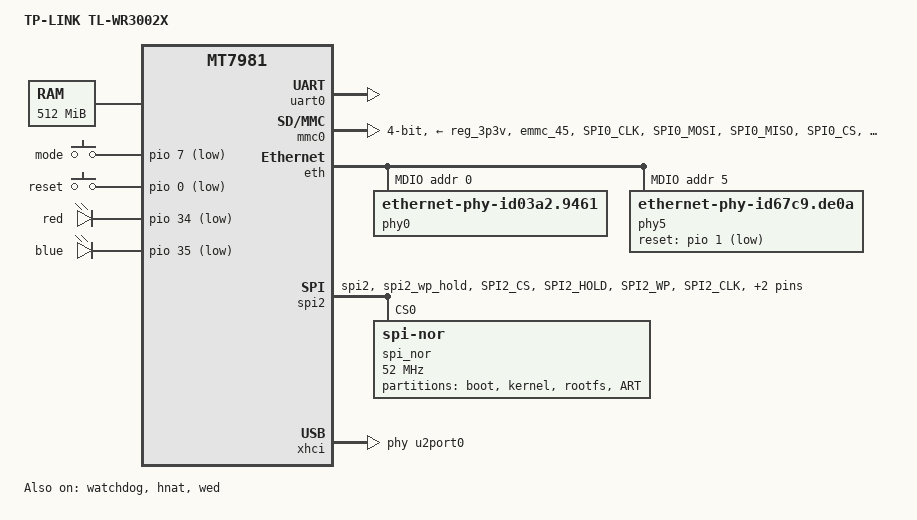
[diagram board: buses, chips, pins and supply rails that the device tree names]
/dts-v1/;
#include "mt7981.dtsi"
/ {
	model = "TP-LINK TL-WR3002X";
	compatible = "tplink,tl-wr3002x-v1", "mediatek,mt7981";
	chosen {
		bootargs = "console=ttyS0,115200n1 loglevel=8  \
				earlycon=uart8250,mmio32,0x11002000";
	};

	memory {
		// fpga ddr2: 512MB
		reg = <0 0x40000000 0 0x20000000>;
	};

	gpio-keys {
		compatible = "gpio-keys";
		mode {
			label = "mode";
			linux,code = <BTN_2>;
			gpios = <&pio 7 GPIO_ACTIVE_LOW>;
		};
	};
	gpio-keys-polled {
		compatible = "gpio-keys-polled";
		poll-interval = <100>;

		reset {
			label = "reset";
			linux,code = <KEY_RESTART>;
			gpios = <&pio 0 GPIO_ACTIVE_LOW>;
			linux,input-type = <1>;
		};
	};
	leds {
		compatible = "gpio-leds";	

		red {
			gpios = <&pio 34 GPIO_ACTIVE_LOW>;
			default-state = "off";
		};
		blue {
			gpios = <&pio 35 GPIO_ACTIVE_LOW>;
			linux,default-trigger = "timer";
		};
	};
};

&uart0 {
	status = "okay";
};

&watchdog {
	status = "okay";
};

&mmc0 {
         pinctrl-names = "default", "state_uhs";
         pinctrl-0 = <&mmc0_pins_default>;
         pinctrl-1 = <&mmc0_pins_uhs>;
         bus-width = <4>;
         max-frequency = <50000000>;
         cap-sd-highspeed;
         cd-gpios = <&pio 5 GPIO_ACTIVE_LOW>;
         wp-gpios = <&pio 8 GPIO_ACTIVE_LOW>;
         vmmc-supply = <&reg_3p3v>;
         vqmmc-supply = <&reg_3p3v>;
         status = "okay";
};

&eth {
        status = "okay";

        gmac0: mac@0 {
                compatible = "mediatek,eth-mac";
                reg = <0>;
                phy-mode = "2500base-x";
                nick-index = <0>;

                fixed-link {
                        speed = <2500>;
                        full-duplex;
                        pause;
                        link-gpio = <&pio 13 0>;
                        phy-handle = <&phy5>;
                        label = "eth0";
                };
        };

        gmac1: mac@1 {
                compatible = "mediatek,eth-mac";
                reg = <1>;
                phy-mode = "gmii";
                phy-handle = <&phy0>;
                nick-index = <1>;
        };

        mdio: mdio-bus {
                #address-cells = <1>;
                #size-cells = <0>;

                phy0: ethernet-phy@0 {
                    compatible = "ethernet-phy-id03a2.9461";
                    reg = <0>;
                    phy-mode = "gmii";
                    nvmem-cells = <&phy_calibration>;
                    nvmem-cell-names = "phy-cal-data";
                };

                phy5: phy@5 {
                        compatible = "ethernet-phy-id67c9.de0a";
                        reg = <5>;
                        reset-gpios = <&pio 1 1>;
                        reset-assert-us = <600>;
                        reset-deassert-us = <20000>;
                        phy-mode = "2500base-x";
                        partner_gmac = <0>;
                };
        };
};

&hnat {
	mtketh-wan = "eth0";
	mtketh-lan = "eth1";
	mtketh-ppd = "eth1";
	mtketh-gmac-mode = <2>;
	mtketh-max-gmac = <2>;
	status = "okay";
};

&spi1 {
	pinctrl-names = "default";
	pinctrl-0 = <&spic_pins>;
	status = "disabled";
};

&spi2 {
	pinctrl-names = "default";
	pinctrl-0 = <&spi2_flash_pins>;
	status = "okay";
	spi_nor@0 {
		#address-cells = <1>;
		#size-cells = <1>;
		compatible = "jedec,spi-nor";
		spi-cal-enable;
		spi-cal-mode = "read-data";
		spi-cal-datalen = <7>;
		spi-cal-data = /bits/ 8 <
			0x53 0x46 0x5F 0x42 0x4F 0x4F 0x54>; /* SF_BOOT */
		spi-cal-addrlen = <1>;
		spi-cal-addr = /bits/ 32 <0x0>;
		reg = <0>;
		spi-max-frequency = <52000000>;
		spi-tx-buswidth = <4>;
		spi-rx-buswidth = <4>;

		partition@00000 {
			label = "boot";
			reg = <0x00000 0x000ff000>;
		};
		partition@100000 {
			label = "kernel";
			reg = <0x100000 0x00400000>;
		};
		partition@500000 {
			label = "rootfs";
			reg = <0x500000 0x019e0000>;
		};
		partition@1ff0000 {
			label = "ART";
			reg = <0x01ff0000 0x00001000>;
		};
	};
};

&pio {
	spic_pins: spi1-pins {
		mux {
			function = "spi";
			groups = "spi1_1";
		};
	};

	spi2_flash_pins: spi2-pins {
		mux {
			function = "spi";
			groups = "spi2", "spi2_wp_hold";
		};

		conf-pu {
			pins = "SPI2_CS", "SPI2_HOLD", "SPI2_WP";
			drive-strength = <MTK_DRIVE_8mA>;
			bias-pull-up = <MTK_PUPD_SET_R1R0_11>;
		};

		conf-pd {
			pins = "SPI2_CLK", "SPI2_MOSI", "SPI2_MISO";
			drive-strength = <MTK_DRIVE_8mA>;
			bias-pull-down = <MTK_PUPD_SET_R1R0_11>;
		};
	};

	mmc0_pins_default: mmc0-pins-default {
		mux {
			function = "flash";
			groups = "emmc_45";
		};
		/* EMMC_DAT0: SPI0_CLK
		 * EMMC_DAT1: SPI0_MOSI
		 * EMMC_DAT2: SPI0_MISO
		 * EMMC_DAT3: SPI0_CS
		 * EMMC_CMD : SPI1_MISO
		 * EMMC_CLK : SPI1_CS
		 */
		conf-cmd-dat {
			pins = "SPI0_CLK", "SPI0_MOSI", "SPI0_MISO",
			       "SPI0_CS", "SPI1_MISO";
			input-enable;
			drive-strength = <MTK_DRIVE_8mA>;
			bias-pull-up = <MTK_PUPD_SET_R1R0_01>;
		};
		conf-clk {
			pins = "SPI1_CS";
			drive-strength = <MTK_DRIVE_12mA>;
			bias-pull-down = <MTK_PUPD_SET_R1R0_10>;
		};
	};

	mmc0_pins_uhs: mmc0-pins-uhs {
		mux {
			function = "flash";
			groups = "emmc_45";
		};
		conf-cmd-dat {
			pins = "SPI0_CLK", "SPI0_MOSI", "SPI0_MISO",
			       "SPI0_CS", "SPI1_MISO";
			input-enable;
			drive-strength = <MTK_DRIVE_8mA>;
			bias-pull-up = <MTK_PUPD_SET_R1R0_01>;
		};
		conf-clk {
			pins = "SPI1_CS";
			drive-strength = <MTK_DRIVE_12mA>;
			bias-pull-down = <MTK_PUPD_SET_R1R0_10>;
		};
	};
};

&xhci {
	mediatek,u3p-dis-msk = <0x0>;
	phys = <&u2port0 PHY_TYPE_USB2>,
	       <&u3port0 PHY_TYPE_USB3>;
	status = "okay";
};

&wed {
	dy_txbm_enable = "true";
	dy_txbm_budget = <8>;
	txbm_init_sz = <8>;
	txbm_max_sz = <32>;
	status = "okay";
};
